# STM32L4x2 register map
File version: 1.6
CPU: CM4 r1p0, little endian, no MPU, no FPU, 3 interrupt priority bits
Registers are 32-bit, read-write, reset 0x0 unless marked. A register's access mark holds for its fields unless they carry their own. Offsets are from the block's base; [hi:lo] are bit positions; lines under a group give offsets from that group; {n}, {i} and the like mark numbered series; 'fields as' and 'values as' point back to an identical list.

## CRC — Cyclic redundancy check calculation unit
Base 0x40023000
0x00 DR reset 0xFFFFFFFF — Data register
  [31:0] DR — Data register bits
0x04 IDR — Independent data register
  [7:0] IDR — General-purpose 8-bit data register bits
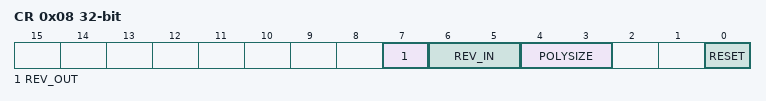
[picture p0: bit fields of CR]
0x08 CR access per field — Control register
  [7] REV_OUT rw — Reverse output data
  [6:5] REV_IN rw — Reverse input data
  [4:3] POLYSIZE rw — Polynomial size
  [0] RESET wo — RESET bit
0x10 INIT reset 0xFFFFFFFF — Initial CRC value
  [31:0] CRC_INIT — Programmable initial CRC value
0x14 POL reset 0x4C11DB7 — polynomial
  [31:0] Polynomialcoefficients — Programmable polynomial

## LCD — Liquid crystal display controller
Base 0x40002400
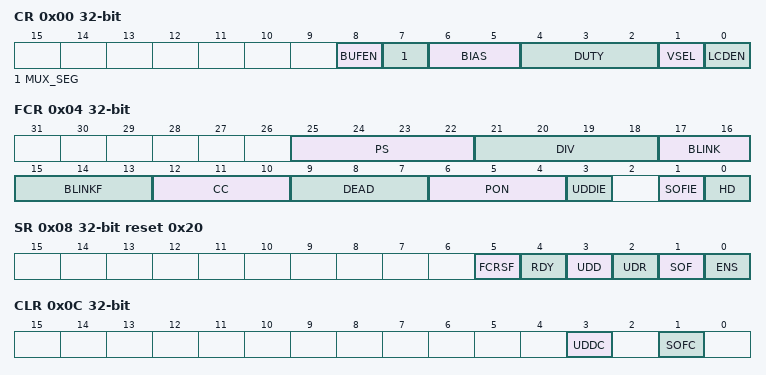
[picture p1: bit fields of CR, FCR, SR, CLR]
0x00 CR — control register
  [8] BUFEN — Voltage output buffer enable
  [7] MUX_SEG — Mux segment enable
  [6:5] BIAS — Bias selector
  [4:2] DUTY — Duty selection
  [1] VSEL — Voltage source selection
  [0] LCDEN — LCD controller enable
0x04 FCR — frame control register
  [25:22] PS — PS 16-bit prescaler
  [21:18] DIV — DIV clock divider
  [17:16] BLINK — Blink mode selection
  [15:13] BLINKF — Blink frequency selection
  [12:10] CC — Contrast control
  [9:7] DEAD — Dead time duration
  [6:4] PON — Pulse ON duration
  [3] UDDIE — Update display done interrupt enable
  [1] SOFIE — Start of frame interrupt enable
  [0] HD — High drive enable
0x08 SR access per field reset 0x20 — status register
  [5] FCRSF ro — LCD Frame Control Register Synchronization flag
  [4] RDY ro — Ready flag
  [3] UDD ro — Update Display Done
  [2] UDR wo — Update display request
  [1] SOF ro — Start of frame flag
  [0] ENS ro
0x0C CLR wo — clear register
  [3] UDDC — Update display done clear
  [1] SOFC — Start of frame flag clear
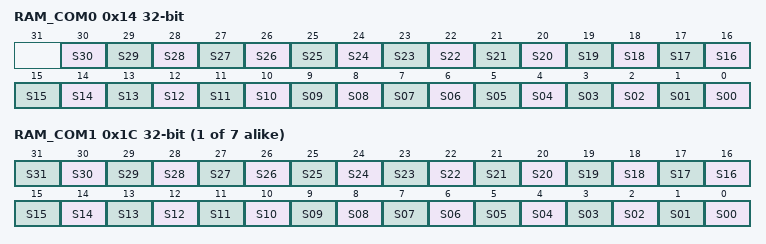
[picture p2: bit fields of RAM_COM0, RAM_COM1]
0x14 RAM_COM0 — display memory
  [n] S{n:02} (n=0..30)
{0x14+8i} RAM_COM{i} (i=1..7) — display memory
  [n] S{n:02} (n=0..31)

## TSC — Touch sensing controller
Base 0x40024000
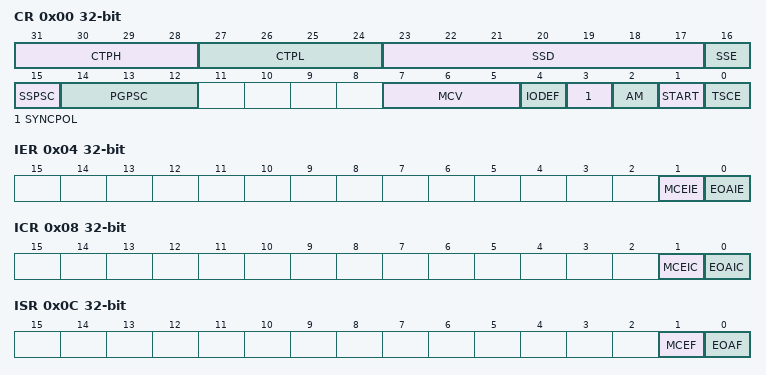
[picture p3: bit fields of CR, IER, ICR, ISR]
0x00 CR — control register
  [31:28] CTPH — Charge transfer pulse high
  [27:24] CTPL — Charge transfer pulse low
  [23:17] SSD — Spread spectrum deviation
  [16] SSE — Spread spectrum enable
  [15] SSPSC — Spread spectrum prescaler
  [14:12] PGPSC — pulse generator prescaler
  [7:5] MCV — Max count value
  [4] IODEF — I/O Default mode
  [3] SYNCPOL — Synchronization pin polarity
  [2] AM — Acquisition mode
  [1] START — Start a new acquisition
  [0] TSCE — Touch sensing controller enable
0x04 IER — interrupt enable register
  [1] MCEIE — Max count error interrupt enable
  [0] EOAIE — End of acquisition interrupt enable
0x08 ICR — interrupt clear register
  [1] MCEIC — Max count error interrupt clear
  [0] EOAIC — End of acquisition interrupt clear
0x0C ISR — interrupt status register
  [1] MCEF — Max count error flag
  [0] EOAF — End of acquisition flag
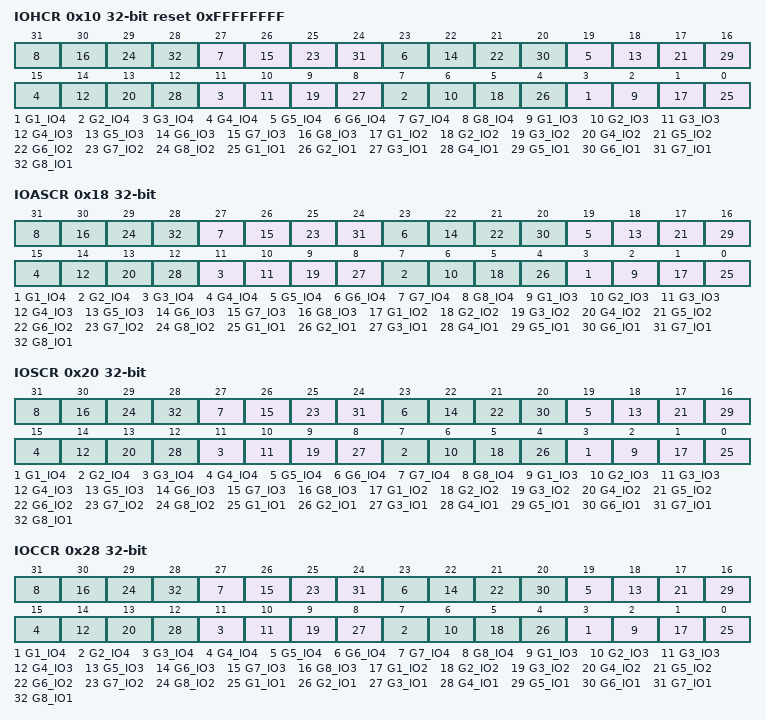
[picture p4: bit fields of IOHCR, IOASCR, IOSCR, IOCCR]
0x10 IOHCR reset 0xFFFFFFFF — I/O hysteresis control register
  [4n-1] G{n}_IO4 (n=1..8), [4n-2] G{n}_IO3 (n=1..8), [4n-3] G{n}_IO2 (n=1..8), [4n-4] G{n}_IO1 (n=1..8)
0x18 IOASCR — I/O analog switch control register
  fields as IOHCR
0x20 IOSCR — I/O sampling control register
  fields as IOHCR
0x28 IOCCR — I/O channel control register
  fields as IOHCR
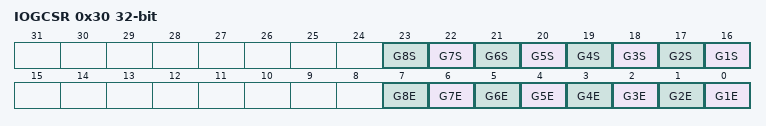
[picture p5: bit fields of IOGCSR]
0x30 IOGCSR access per field — I/O group control status register
  [n+15] G{n}S ro (n=1..8) — Analog I/O group x status
  [n-1] G{n}E rw (n=1..8) — Analog I/O group x enable
{0x30+4i} IOG{i}CR ro (i=1..8) — I/O group x counter register
  [13:0] CNT — Counter value

## IWDG — Independent watchdog
Base 0x40003000
0x00 KR wo — Key register
  [15:0] KEY — Key value (write only, read 0x0000)
0x04 PR — Prescaler register
  [2:0] PR — Prescaler divider
0x08 RLR reset 0xFFF — Reload register
  [11:0] RL — Watchdog counter reload value
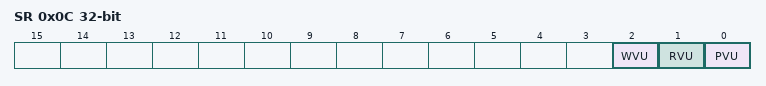
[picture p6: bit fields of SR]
0x0C SR ro — Status register
  [2] WVU — Watchdog counter window value update
  [1] RVU — Watchdog counter reload value update
  [0] PVU — Watchdog prescaler value update
0x10 WINR reset 0xFFF — Window register
  [11:0] WIN — Watchdog counter window value
